AUTOSAR XML (schema 4-0-3)
package /ComponentTypes
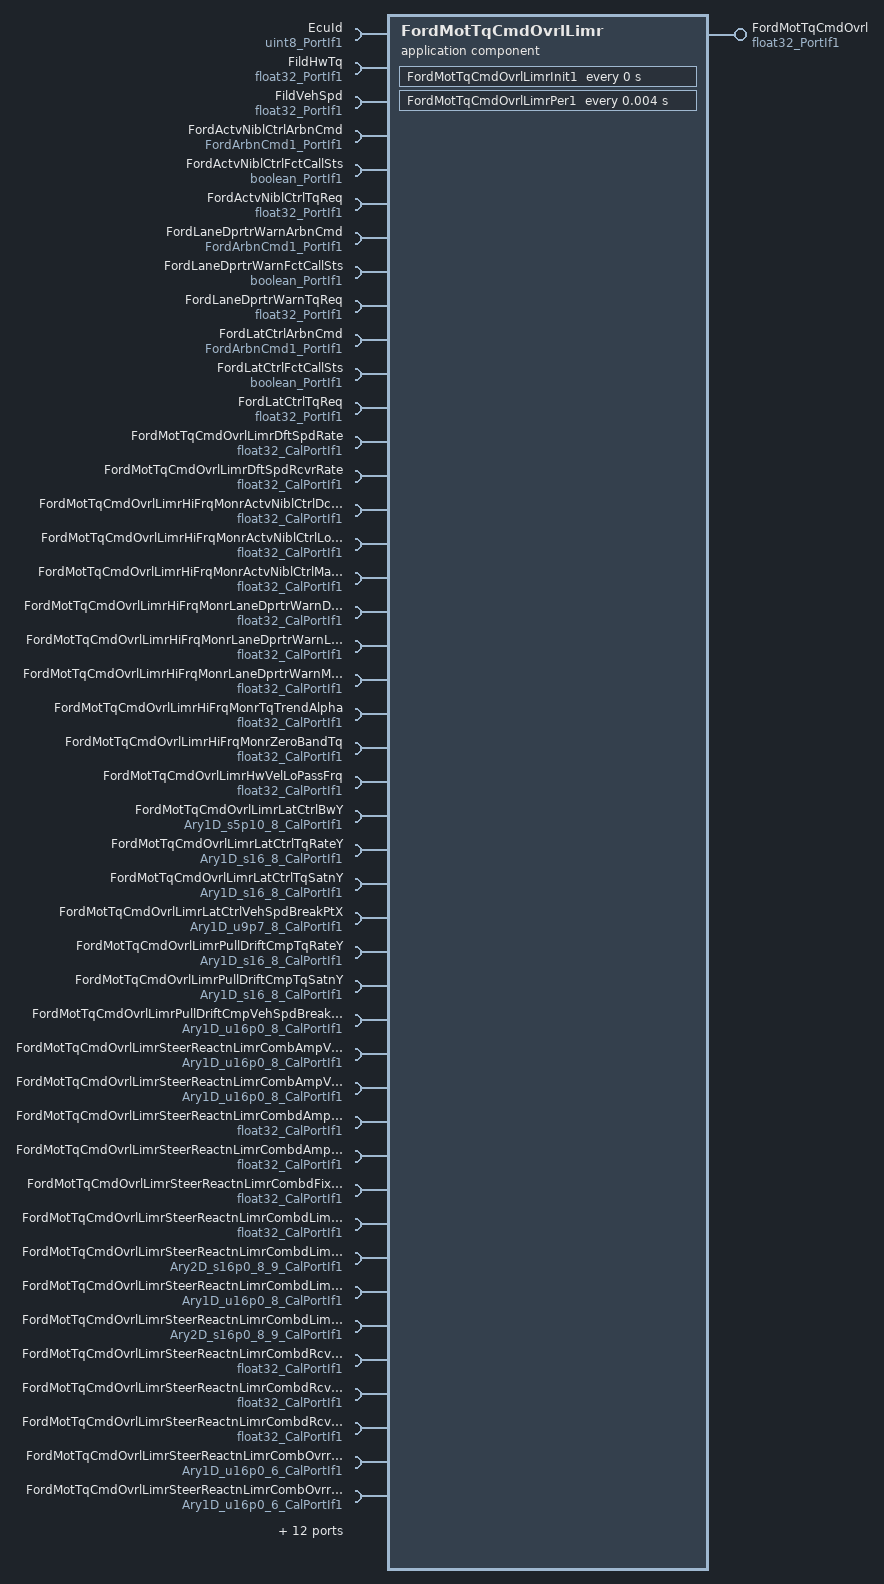
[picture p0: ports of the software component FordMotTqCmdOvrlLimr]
  application sw component type FordMotTqCmdOvrlLimr
    provide port FordMotTqCmdOvrl: nonqueued-sender-com-spec{data-element=Val, init-value=0}, provided-interface=float32_PortIf1
    56 x require port:
      EcuId: nonqueued-receiver-com-spec{data-element=Val, filter=data-filter-type=ALWAYS, init-value=0}, required-interface=uint8_PortIf1
      FildHwTq: nonqueued-receiver-com-spec{data-element=Val, filter=data-filter-type=ALWAYS, init-value=0}, required-interface=float32_PortIf1
      FildVehSpd: nonqueued-receiver-com-spec{data-element=Val, filter=data-filter-type=ALWAYS, init-value=0}, required-interface=float32_PortIf1
      FordActvNiblCtrlArbnCmd: nonqueued-receiver-com-spec{data-element=Val, filter=data-filter-type=ALWAYS, init-value=0}, required-interface=FordArbnCmd1_PortIf1
      FordActvNiblCtrlFctCallSts: nonqueued-receiver-com-spec{data-element=Logl, filter=data-filter-type=ALWAYS, init-value=0}, required-interface=boolean_PortIf1
      FordActvNiblCtrlTqReq: nonqueued-receiver-com-spec{data-element=Val, filter=data-filter-type=ALWAYS, init-value=0}, required-interface=float32_PortIf1
      FordLaneDprtrWarnArbnCmd: nonqueued-receiver-com-spec{data-element=Val, filter=data-filter-type=ALWAYS, init-value=0}, required-interface=FordArbnCmd1_PortIf1
      FordLaneDprtrWarnFctCallSts: nonqueued-receiver-com-spec{data-element=Logl, filter=data-filter-type=ALWAYS, init-value=0}, required-interface=boolean_PortIf1
      FordLaneDprtrWarnTqReq: nonqueued-receiver-com-spec{data-element=Val, filter=data-filter-type=ALWAYS, init-value=0}, required-interface=float32_PortIf1
      FordLatCtrlArbnCmd: nonqueued-receiver-com-spec{data-element=Val, filter=data-filter-type=ALWAYS, init-value=0}, required-interface=FordArbnCmd1_PortIf1
      FordLatCtrlFctCallSts: nonqueued-receiver-com-spec{data-element=Logl, filter=data-filter-type=ALWAYS, init-value=0}, required-interface=boolean_PortIf1
      FordLatCtrlTqReq: nonqueued-receiver-com-spec{data-element=Val, filter=data-filter-type=ALWAYS, init-value=0}, required-interface=float32_PortIf1
      FordMotTqCmdOvrlLimrDftSpdRate: parameter-require-com-spec{init-value=40, parameter=Val}, required-interface=float32_CalPortIf1
      FordMotTqCmdOvrlLimrDftSpdRcvrRate: parameter-require-com-spec{init-value=40, parameter=Val}, required-interface=float32_CalPortIf1
      FordMotTqCmdOvrlLimrHiFrqMonrActvNiblCtrlDcTqTrendThd: parameter-require-com-spec{init-value=1, parameter=Val}, required-interface=float32_CalPortIf1
      FordMotTqCmdOvrlLimrHiFrqMonrActvNiblCtrlLoFrqTiThd: parameter-require-com-spec{init-value=0.1, parameter=Val}, required-interface=float32_CalPortIf1
      FordMotTqCmdOvrlLimrHiFrqMonrActvNiblCtrlMaxMotTq: parameter-require-com-spec{init-value=5, parameter=Val}, required-interface=float32_CalPortIf1
      FordMotTqCmdOvrlLimrHiFrqMonrLaneDprtrWarnDcTqTrendThd: parameter-require-com-spec{init-value=1.5, parameter=Val}, required-interface=float32_CalPortIf1
      FordMotTqCmdOvrlLimrHiFrqMonrLaneDprtrWarnLoFrqTiThd: parameter-require-com-spec{init-value=0.033, parameter=Val}, required-interface=float32_CalPortIf1
      FordMotTqCmdOvrlLimrHiFrqMonrLaneDprtrWarnMaxMotTq: parameter-require-com-spec{init-value=5.5, parameter=Val}, required-interface=float32_CalPortIf1
      FordMotTqCmdOvrlLimrHiFrqMonrTqTrendAlpha: parameter-require-com-spec{init-value=1, parameter=Val}, required-interface=float32_CalPortIf1
      FordMotTqCmdOvrlLimrHiFrqMonrZeroBandTq: parameter-require-com-spec{init-value=1, parameter=Val}, required-interface=float32_CalPortIf1
      FordMotTqCmdOvrlLimrHwVelLoPassFrq: parameter-require-com-spec{init-value=0, parameter=Val}, required-interface=float32_CalPortIf1
      FordMotTqCmdOvrlLimrLatCtrlBwY: parameter-require-com-spec{init-value=8 x 0, parameter=Val}, required-interface=Ary1D_s5p10_8_CalPortIf1
      FordMotTqCmdOvrlLimrLatCtrlTqRateY: parameter-require-com-spec{init-value=8 x 5, parameter=Ary1D}, required-interface=Ary1D_s16_8_CalPortIf1
      FordMotTqCmdOvrlLimrLatCtrlTqSatnY: parameter-require-com-spec{init-value=8 x 0, parameter=Ary1D}, required-interface=Ary1D_s16_8_CalPortIf1
      FordMotTqCmdOvrlLimrLatCtrlVehSpdBreakPtX: parameter-require-com-spec{init-value=[0, 15, 60, 100, 150, 180, 200, 250], parameter=Ary1D}, required-interface=Ary1D_u9p7_8_CalPortIf1
      FordMotTqCmdOvrlLimrPullDriftCmpTqRateY: parameter-require-com-spec{init-value=8 x 1, parameter=Ary1D}, required-interface=Ary1D_s16_8_CalPortIf1
      FordMotTqCmdOvrlLimrPullDriftCmpTqSatnY: parameter-require-com-spec{init-value=8 x 3, parameter=Ary1D}, required-interface=Ary1D_s16_8_CalPortIf1
      FordMotTqCmdOvrlLimrPullDriftCmpVehSpdBreakPtX: parameter-require-com-spec{init-value=[0, 15, 60, 100, 150, 180, 200, 250], parameter=Ary1D}, required-interface=Ary1D_u16p0_8_CalPortIf1
      FordMotTqCmdOvrlLimrSteerReactnLimrCombAmpVehSpdLimX: parameter-require-com-spec{init-value=8 x 0, parameter=Ary1D}, required-interface=Ary1D_u16p0_8_CalPortIf1
      FordMotTqCmdOvrlLimrSteerReactnLimrCombAmpVehSpdLimY: parameter-require-com-spec{init-value=[0, 15, 40, 70, 100, 150, 200, 250], parameter=Ary1D}, required-interface=Ary1D_u16p0_8_CalPortIf1
      FordMotTqCmdOvrlLimrSteerReactnLimrCombdAmpOvrrun: parameter-require-com-spec{init-value=0, parameter=Val}, required-interface=float32_CalPortIf1
      FordMotTqCmdOvrlLimrSteerReactnLimrCombdAmpRcvry: parameter-require-com-spec{init-value=0.5, parameter=Val}, required-interface=float32_CalPortIf1
      FordMotTqCmdOvrlLimrSteerReactnLimrCombdFixdOvrrunRampRate: parameter-require-com-spec{init-value=8, parameter=Val}, required-interface=float32_CalPortIf1
      FordMotTqCmdOvrlLimrSteerReactnLimrCombdLimHys: parameter-require-com-spec{init-value=0.05, parameter=Val}, required-interface=float32_CalPortIf1
      FordMotTqCmdOvrlLimrSteerReactnLimrCombdLimrHwVelY: parameter-require-com-spec{init-value=[[-20, 10, 20, 30, 80, 100, 100, 100, 100], [-20, 10, 20, 30, 80, 100, 100, 100, 100], [-20, 10, 20, 20, 80, 100, 100, 100, 100], [-20, 10, 20, 20, 80, 100, 100, 100, 100], [-40, 5, 10, 15, 60, 80, 80, 80, 80], [-40, 0, 5, 10, 30, 40, 40, 40, 40], [-40, 0, 5, 10, 20, 30, 30, 30, 30], [-40, 0, 5, 10, 20, 30, 30, 30, 30]], parameter=Ary2D}, required-interface=Ary2D_s16p0_8_9_CalPortIf1
      FordMotTqCmdOvrlLimrSteerReactnLimrCombdLimrVehSpd: parameter-require-com-spec{init-value=[0, 15, 40, 70, 100, 150, 200, 250], parameter=Ary1D}, required-interface=Ary1D_u16p0_8_CalPortIf1
      FordMotTqCmdOvrlLimrSteerReactnLimrCombdLimTqX: parameter-require-com-spec{init-value=8 x [-6, -5, -4, -2, 0, 2, 4, 5, 6], parameter=Ary2D}, required-interface=Ary2D_s16p0_8_9_CalPortIf1
      FordMotTqCmdOvrlLimrSteerReactnLimrCombdRcvryIdealRampRate: parameter-require-com-spec{init-value=0, parameter=Val}, required-interface=float32_CalPortIf1
      FordMotTqCmdOvrlLimrSteerReactnLimrCombdRcvryRampRateStg1: parameter-require-com-spec{init-value=20, parameter=Val}, required-interface=float32_CalPortIf1
      FordMotTqCmdOvrlLimrSteerReactnLimrCombdRcvryRampRateStg2: parameter-require-com-spec{init-value=40, parameter=Val}, required-interface=float32_CalPortIf1
      FordMotTqCmdOvrlLimrSteerReactnLimrCombOvrrunRampRateHwVelErrX: parameter-require-com-spec{init-value=[0, 25, 50, 70, 170, 250], parameter=Ary1D}, required-interface=Ary1D_u16p0_6_CalPortIf1
      FordMotTqCmdOvrlLimrSteerReactnLimrCombOvrrunRampRateOutY: parameter-require-com-spec{init-value=[0, 35, 70, 130, 300, 600], parameter=Ary1D}, required-interface=Ary1D_u16p0_6_CalPortIf1
      FordPullDriftCmpArbnCmd: nonqueued-receiver-com-spec{data-element=Val, filter=data-filter-type=ALWAYS, init-value=0}, required-interface=FordArbnCmd1_PortIf1
      FordPullDriftCmpFctCallSts: nonqueued-receiver-com-spec{data-element=Logl, filter=data-filter-type=ALWAYS, init-value=0}, required-interface=boolean_PortIf1
      FordPullDriftCmpTqReq: nonqueued-receiver-com-spec{data-element=Val, filter=data-filter-type=ALWAYS, init-value=0}, required-interface=float32_PortIf1
      FordSteerTqDstbcRejctnArbnCmd: nonqueued-receiver-com-spec{data-element=Val, filter=data-filter-type=ALWAYS, init-value=0}, required-interface=FordArbnCmd1_PortIf1
      FordSteerTqDstbcRejctnFctCallSts: nonqueued-receiver-com-spec{data-element=Logl, filter=data-filter-type=ALWAYS, init-value=0}, required-interface=boolean_PortIf1
      FordSteerTqDstbcRejctnTqReq: nonqueued-receiver-com-spec{data-element=Val, filter=data-filter-type=ALWAYS, init-value=0}, required-interface=float32_PortIf1
      GetRefTmr100MicroSec32bit: client-com-spec=Oper, required-interface=GetRefTmr100MicroSec32bit_PortIf1
      GetSigImcData_f32: client-com-spec=Oper, required-interface=GetSigImcData_f32_PortIf1
      GetTiSpan100MicroSec32bit: client-com-spec=Oper, required-interface=GetTiSpan100MicroSec32bit_PortIf1
      HwVel: nonqueued-receiver-com-spec{data-element=Val, filter=data-filter-type=ALWAYS, init-value=0}, required-interface=float32_PortIf1
      SetNtcSts: client-com-spec=Oper, required-interface=SetNtcSts_PortIf1
      VehSpdVld: nonqueued-receiver-com-spec{data-element=Logl, filter=data-filter-type=ALWAYS, init-value=0}, required-interface=boolean_PortIf1
    behavior FordMotTqCmdOvrlLimr_InternalBehavior
      ar-typed-per-instance-memorys:
        18 x data, all with sw-calibration-access=READ-ONLY:
          ActvNiblCtrlLoFrqElpdTiVari: type=uint32
          ActvNiblCtrlLoFrqFlt: type=uint8
          ActvNiblCtrlLoFrqSt: type=uint8
          ActvNiblCtrlLoFrqTmrFlgVari: type=boolean
          ActvNiblCtrlLoFrqTmrVari: type=uint32
          DftVehSpd: type=float32
          HwVelFil: type=FilLpRec1
          LaneDprtrWarnLoFrqElpdTiVari: type=uint32
          LaneDprtrWarnLoFrqFlt: type=uint8
          LaneDprtrWarnLoFrqSt: type=uint8
          LaneDprtrWarnLoFrqTmrFlgVari: type=boolean
          LaneDprtrWarnLoFrqTmrVari: type=uint32
          LimrDftVehSpd: type=boolean
          PrevAmpLim: type=float32
          PrevDftVehSpd: type=float32
          PrevLimdTqReq: type=float32
          PrevLimrVehSpd: type=float32
          PrevTqTrend: type=float32
      timing event FordMotTqCmdOvrlLimr_InitEvent: start-on-event=FordMotTqCmdOvrlLimrInit1, period=0
      timing event TMT_FordMotTqCmdOvrlLimrPer1: start-on-event=FordMotTqCmdOvrlLimrPer1, period=0.004
      port-api-options:
        enable-take-address=false, indirect-api=false, port=EcuId
        enable-take-address=false, indirect-api=false, port=FildHwTq
        enable-take-address=false, indirect-api=false, port=FildVehSpd
        enable-take-address=false, indirect-api=false, port=FordActvNiblCtrlArbnCmd
        enable-take-address=false, indirect-api=false, port=FordActvNiblCtrlFctCallSts
        enable-take-address=false, indirect-api=false, port=FordActvNiblCtrlTqReq
        enable-take-address=false, indirect-api=false, port=FordLaneDprtrWarnArbnCmd
        enable-take-address=false, indirect-api=false, port=FordLaneDprtrWarnFctCallSts
        enable-take-address=false, indirect-api=false, port=FordLaneDprtrWarnTqReq
        enable-take-address=false, indirect-api=false, port=FordLatCtrlArbnCmd
        enable-take-address=false, indirect-api=false, port=FordLatCtrlFctCallSts
        enable-take-address=false, indirect-api=false, port=FordLatCtrlTqReq
        enable-take-address=false, indirect-api=false, port=FordMotTqCmdOvrl
        enable-take-address=false, indirect-api=false, port=FordMotTqCmdOvrlLimrDftSpdRate
        enable-take-address=false, indirect-api=false, port=FordMotTqCmdOvrlLimrDftSpdRcvrRate
        enable-take-address=false, indirect-api=false, port=FordMotTqCmdOvrlLimrHiFrqMonrActvNiblCtrlDcTqTrendThd
        enable-take-address=false, indirect-api=false, port=FordMotTqCmdOvrlLimrHiFrqMonrActvNiblCtrlLoFrqTiThd
        enable-take-address=false, indirect-api=false, port=FordMotTqCmdOvrlLimrHiFrqMonrActvNiblCtrlMaxMotTq
        enable-take-address=false, indirect-api=false, port=FordMotTqCmdOvrlLimrHiFrqMonrLaneDprtrWarnDcTqTrendThd
        enable-take-address=false, indirect-api=false, port=FordMotTqCmdOvrlLimrHiFrqMonrLaneDprtrWarnLoFrqTiThd
        enable-take-address=false, indirect-api=false, port=FordMotTqCmdOvrlLimrHiFrqMonrLaneDprtrWarnMaxMotTq
        enable-take-address=false, indirect-api=false, port=FordMotTqCmdOvrlLimrHiFrqMonrTqTrendAlpha
        enable-take-address=false, indirect-api=false, port=FordMotTqCmdOvrlLimrHiFrqMonrZeroBandTq
        enable-take-address=false, indirect-api=false, port=FordMotTqCmdOvrlLimrHwVelLoPassFrq
        enable-take-address=false, indirect-api=false, port=FordMotTqCmdOvrlLimrLatCtrlBwY
        enable-take-address=false, indirect-api=false, port=FordMotTqCmdOvrlLimrLatCtrlTqRateY
        enable-take-address=false, indirect-api=false, port=FordMotTqCmdOvrlLimrLatCtrlTqSatnY
        enable-take-address=false, indirect-api=false, port=FordMotTqCmdOvrlLimrLatCtrlVehSpdBreakPtX
        enable-take-address=false, indirect-api=false, port=FordMotTqCmdOvrlLimrPullDriftCmpTqRateY
        enable-take-address=false, indirect-api=false, port=FordMotTqCmdOvrlLimrPullDriftCmpTqSatnY
        enable-take-address=false, indirect-api=false, port=FordMotTqCmdOvrlLimrPullDriftCmpVehSpdBreakPtX
        enable-take-address=false, indirect-api=false, port=FordMotTqCmdOvrlLimrSteerReactnLimrCombAmpVehSpdLimX
        enable-take-address=false, indirect-api=false, port=FordMotTqCmdOvrlLimrSteerReactnLimrCombAmpVehSpdLimY
        enable-take-address=false, indirect-api=false, port=FordMotTqCmdOvrlLimrSteerReactnLimrCombdAmpOvrrun
        enable-take-address=false, indirect-api=false, port=FordMotTqCmdOvrlLimrSteerReactnLimrCombdAmpRcvry
        enable-take-address=false, indirect-api=false, port=FordMotTqCmdOvrlLimrSteerReactnLimrCombdFixdOvrrunRampRate
        enable-take-address=false, indirect-api=false, port=FordMotTqCmdOvrlLimrSteerReactnLimrCombdLimHys
        enable-take-address=false, indirect-api=false, port=FordMotTqCmdOvrlLimrSteerReactnLimrCombdLimrHwVelY
        enable-take-address=false, indirect-api=false, port=FordMotTqCmdOvrlLimrSteerReactnLimrCombdLimrVehSpd
        enable-take-address=false, indirect-api=false, port=FordMotTqCmdOvrlLimrSteerReactnLimrCombdLimTqX
        enable-take-address=false, indirect-api=false, port=FordMotTqCmdOvrlLimrSteerReactnLimrCombdRcvryIdealRampRate
        enable-take-address=false, indirect-api=false, port=FordMotTqCmdOvrlLimrSteerReactnLimrCombdRcvryRampRateStg1
        enable-take-address=false, indirect-api=false, port=FordMotTqCmdOvrlLimrSteerReactnLimrCombdRcvryRampRateStg2
        enable-take-address=false, indirect-api=false, port=FordMotTqCmdOvrlLimrSteerReactnLimrCombOvrrunRampRateHwVelErrX
        enable-take-address=false, indirect-api=false, port=FordMotTqCmdOvrlLimrSteerReactnLimrCombOvrrunRampRateOutY
        enable-take-address=false, indirect-api=false, port=FordPullDriftCmpArbnCmd
        enable-take-address=false, indirect-api=false, port=FordPullDriftCmpFctCallSts
        enable-take-address=false, indirect-api=false, port=FordPullDriftCmpTqReq
        enable-take-address=false, indirect-api=false, port=FordSteerTqDstbcRejctnArbnCmd
        enable-take-address=false, indirect-api=false, port=FordSteerTqDstbcRejctnFctCallSts
        enable-take-address=false, indirect-api=false, port=FordSteerTqDstbcRejctnTqReq
        enable-take-address=false, indirect-api=false, port=GetRefTmr100MicroSec32bit
        enable-take-address=false, indirect-api=false, port=GetSigImcData_f32
        enable-take-address=false, indirect-api=false, port=GetTiSpan100MicroSec32bit
        enable-take-address=false, indirect-api=false, port=HwVel
        enable-take-address=false, indirect-api=false, port=SetNtcSts
        enable-take-address=false, indirect-api=false, port=VehSpdVld
      runnable FordMotTqCmdOvrlLimrInit1
        sync call SC_SetNtcSts_PortIf1_Oper: operation=SetNtcSts.Oper, timeout=0
      runnable FordMotTqCmdOvrlLimrPer1
        data-receive-point-by-arguments:
          20 x access:
            REC_EcuId_Val: accessed-variable=EcuId.Val
            REC_FildHwTq_Val: accessed-variable=FildHwTq.Val
            REC_FildVehSpd_Val: accessed-variable=FildVehSpd.Val
            REC_FordActvNiblCtrlArbnCmd_Val: accessed-variable=FordActvNiblCtrlArbnCmd.Val
            REC_FordActvNiblCtrlFctCallSts_Logl: accessed-variable=FordActvNiblCtrlFctCallSts.Logl
            REC_FordActvNiblCtrlTqReq_Val: accessed-variable=FordActvNiblCtrlTqReq.Val
            REC_FordLaneDprtrWarnArbnCmd_Val: accessed-variable=FordLaneDprtrWarnArbnCmd.Val
            REC_FordLaneDprtrWarnFctCallSts_Logl: accessed-variable=FordLaneDprtrWarnFctCallSts.Logl
            REC_FordLaneDprtrWarnTqReq_Val: accessed-variable=FordLaneDprtrWarnTqReq.Val
            REC_FordLatCtrlArbnCmd_Val: accessed-variable=FordLatCtrlArbnCmd.Val
            REC_FordLatCtrlFctCallSts_Logl: accessed-variable=FordLatCtrlFctCallSts.Logl
            REC_FordLatCtrlTqReq_Val: accessed-variable=FordLatCtrlTqReq.Val
            REC_FordPullDriftCmpArbnCmd_Val: accessed-variable=FordPullDriftCmpArbnCmd.Val
            REC_FordPullDriftCmpFctCallSts_Logl: accessed-variable=FordPullDriftCmpFctCallSts.Logl
            REC_FordPullDriftCmpTqReq_Val: accessed-variable=FordPullDriftCmpTqReq.Val
            REC_FordSteerTqDstbcRejctnArbnCmd_Val: accessed-variable=FordSteerTqDstbcRejctnArbnCmd.Val
            REC_FordSteerTqDstbcRejctnFctCallSts_Logl: accessed-variable=FordSteerTqDstbcRejctnFctCallSts.Logl
            REC_FordSteerTqDstbcRejctnTqReq_Val: accessed-variable=FordSteerTqDstbcRejctnTqReq.Val
            REC_HwVel_Val: accessed-variable=HwVel.Val
            REC_VehSpdVld_Logl: accessed-variable=VehSpdVld.Logl
        data-send-points:
          access SEND_FordMotTqCmdOvrl_Val: accessed-variable=FordMotTqCmdOvrl.Val
        4 x sync call, all with timeout=0:
          SC_GetRefTmr100MicroSec32bit_PortIf1_Oper: operation=GetRefTmr100MicroSec32bit.Oper
          SC_GetSigImcData_f32_PortIf1_Oper: operation=GetSigImcData_f32.Oper
          SC_GetTiSpan100MicroSec32bit_PortIf1_Oper: operation=GetTiSpan100MicroSec32bit.Oper
          SC_SetNtcSts_PortIf1_Oper: operation=SetNtcSts.Oper
  swc implementation FordMotTqCmdOvrlLimr_Implementation: behavior=FordMotTqCmdOvrlLimr_InternalBehavior
    code-descriptors:
      code Default: artifact-descriptors=autosar-engineering-object={short-label=Default, category=SWSRC}
